# RL7005_IP_SVD register map
Vendor: Realtek
Registers are 32-bit, read-write, reset 0x0 unless marked. A register's access mark holds for its fields unless they carry their own. Offsets are from the block's base; [hi:lo] are bit positions; {n}, {i} and the like mark numbered series.

## TXPWR_CTRL (part 2 of 2)
Base 0x40000000
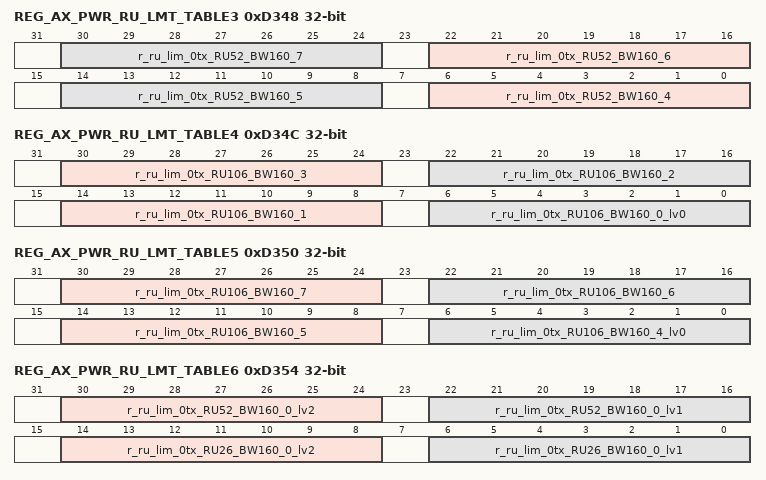
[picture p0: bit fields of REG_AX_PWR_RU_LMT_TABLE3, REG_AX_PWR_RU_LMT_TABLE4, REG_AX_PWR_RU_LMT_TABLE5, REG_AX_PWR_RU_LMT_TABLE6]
0xD348 REG_AX_PWR_RU_LMT_TABLE3
  [8n-26:8n-32] r_ru_lim_0tx_RU52_BW160_{n} (n=4..7) — s(7.1)
0xD34C REG_AX_PWR_RU_LMT_TABLE4
  [30:24] r_ru_lim_0tx_RU106_BW160_3 — s(7.1)
  [22:16] r_ru_lim_0tx_RU106_BW160_2 — s(7.1)
  [14:8] r_ru_lim_0tx_RU106_BW160_1 — s(7.1)
  [6:0] r_ru_lim_0tx_RU106_BW160_0_lv0 — s(7.1)
0xD350 REG_AX_PWR_RU_LMT_TABLE5
  [30:24] r_ru_lim_0tx_RU106_BW160_7 — s(7.1)
  [22:16] r_ru_lim_0tx_RU106_BW160_6 — s(7.1)
  [14:8] r_ru_lim_0tx_RU106_BW160_5 — s(7.1)
  [6:0] r_ru_lim_0tx_RU106_BW160_4_lv0 — s(7.1)
0xD354 REG_AX_PWR_RU_LMT_TABLE6
  [30:24] r_ru_lim_0tx_RU52_BW160_0_lv2 — s(7.1)
  [22:16] r_ru_lim_0tx_RU52_BW160_0_lv1 — s(7.1)
  [14:8] r_ru_lim_0tx_RU26_BW160_0_lv2 — s(7.1)
  [6:0] r_ru_lim_0tx_RU26_BW160_0_lv1 — s(7.1)
0xD358 REG_AX_PWR_RU_LMT_TABLE7
  [6:0] r_ru_lim_0tx_RU106_BW160_0_lv1 — s(7.1)
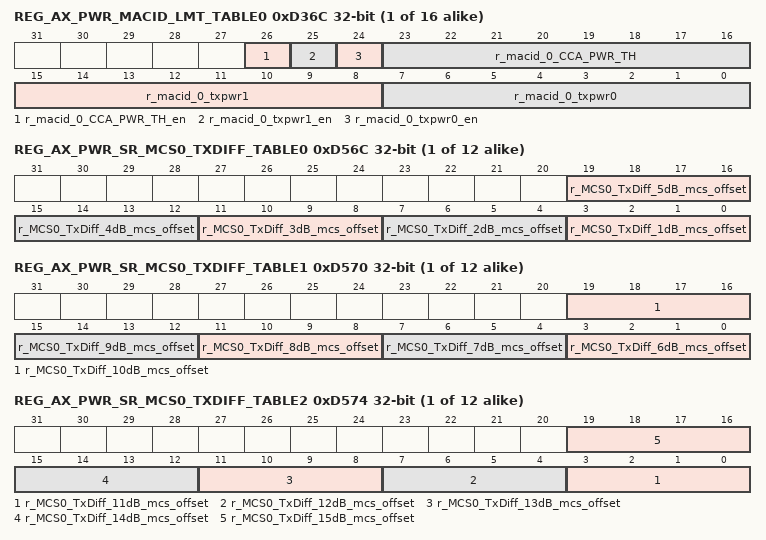
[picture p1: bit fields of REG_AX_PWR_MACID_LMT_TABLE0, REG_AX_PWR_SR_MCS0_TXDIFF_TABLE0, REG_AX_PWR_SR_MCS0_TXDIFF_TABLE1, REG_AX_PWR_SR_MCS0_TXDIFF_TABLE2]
{0xD36C+4i} REG_AX_PWR_MACID_LMT_TABLE{i} (i=0..15)
  [26] r_macid_{i}_CCA_PWR_TH_en — u(1.0)
  [25] r_macid_{i}_txpwr1_en — u(1.0)
  [24] r_macid_{i}_txpwr0_en — u(1.0)
  [23:16] r_macid_{i}_CCA_PWR_TH — s(8.1)
  [15:8] r_macid_{i}_txpwr1 — s(8.1)
  [7:0] r_macid_{i}_txpwr0 — s(8.1)
{0xD56C+0x10*i} REG_AX_PWR_SR_MCS{i}_TXDIFF_TABLE0 (i=0..11)
  [4n-1:4n-4] r_MCS{i}_TxDiff_{n}dB_mcs_offset (n=1..5) — U(4.0) mcs0~11
{0xD570+0x10*i} REG_AX_PWR_SR_MCS{i}_TXDIFF_TABLE1 (i=0..11)
  [4n-21:4n-24] r_MCS{i}_TxDiff_{n}dB_mcs_offset (n=6..10) — U(4.0) mcs0~11
{0xD574+0x10*i} REG_AX_PWR_SR_MCS{i}_TXDIFF_TABLE2 (i=0..11)
  [4n-41:4n-44] r_MCS{i}_TxDiff_{n}dB_mcs_offset (n=11..15) — U(4.0) mcs0~11
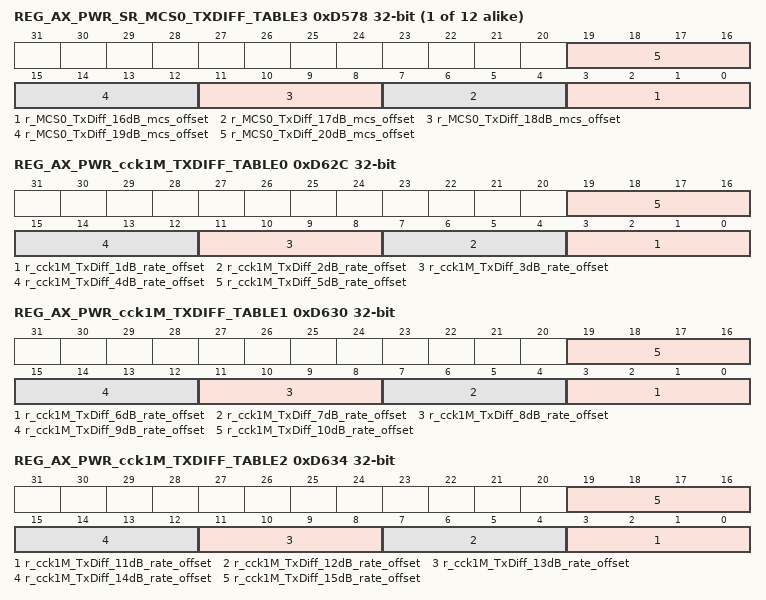
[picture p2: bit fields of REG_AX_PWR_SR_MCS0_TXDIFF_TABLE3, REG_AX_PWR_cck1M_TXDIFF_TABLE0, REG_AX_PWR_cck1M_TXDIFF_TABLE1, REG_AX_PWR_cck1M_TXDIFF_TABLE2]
{0xD578+0x10*i} REG_AX_PWR_SR_MCS{i}_TXDIFF_TABLE3 (i=0..11)
  [4n-61:4n-64] r_MCS{i}_TxDiff_{n}dB_mcs_offset (n=16..20) — U(4.0) mcs0~11
0xD62C REG_AX_PWR_cck1M_TXDIFF_TABLE0
  [4n-1:4n-4] r_cck1M_TxDiff_{n}dB_rate_offset (n=1..5) — U(4.0) cck 0~3, 0-cck1M,1=cck2M,2=cck5p5M,3=cck11M
0xD630 REG_AX_PWR_cck1M_TXDIFF_TABLE1
  [4n-21:4n-24] r_cck1M_TxDiff_{n}dB_rate_offset (n=6..10) — U(4.0) cck 0~3, 0-cck1M,1=cck2M,2=cck5p5M,3=cck11M
0xD634 REG_AX_PWR_cck1M_TXDIFF_TABLE2
  [4n-41:4n-44] r_cck1M_TxDiff_{n}dB_rate_offset (n=11..15) — U(4.0) cck 0~3, 0-cck1M,1=cck2M,2=cck5p5M,3=cck11M
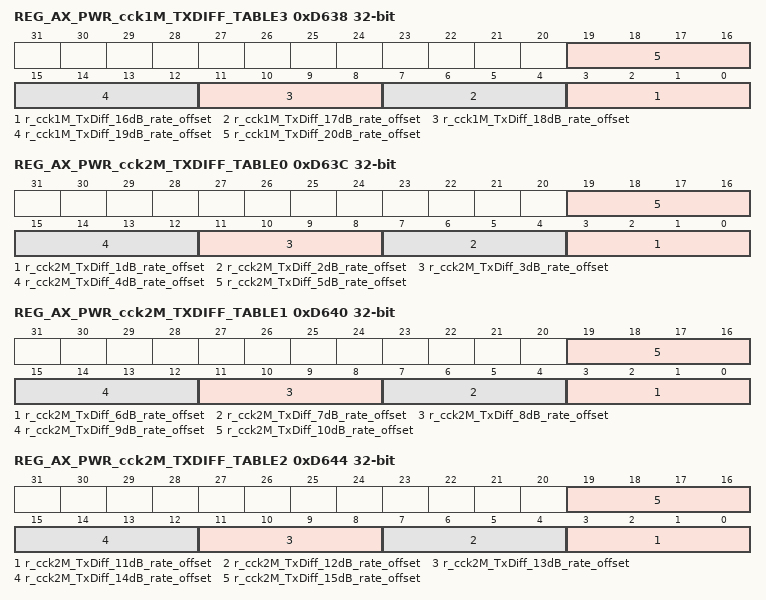
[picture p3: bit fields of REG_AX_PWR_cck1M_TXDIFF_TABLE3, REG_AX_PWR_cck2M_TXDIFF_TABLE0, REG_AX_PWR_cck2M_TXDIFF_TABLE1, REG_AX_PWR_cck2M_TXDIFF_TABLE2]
0xD638 REG_AX_PWR_cck1M_TXDIFF_TABLE3
  [4n-61:4n-64] r_cck1M_TxDiff_{n}dB_rate_offset (n=16..20) — U(4.0) cck 0~3, 0-cck1M,1=cck2M,2=cck5p5M,3=cck11M
0xD63C REG_AX_PWR_cck2M_TXDIFF_TABLE0
  [4n-1:4n-4] r_cck2M_TxDiff_{n}dB_rate_offset (n=1..5) — U(4.0) cck 0~3, 0-cck1M,1=cck2M,2=cck5p5M,3=cck11M
0xD640 REG_AX_PWR_cck2M_TXDIFF_TABLE1
  [4n-21:4n-24] r_cck2M_TxDiff_{n}dB_rate_offset (n=6..10) — U(4.0) cck 0~3, 0-cck1M,1=cck2M,2=cck5p5M,3=cck11M
0xD644 REG_AX_PWR_cck2M_TXDIFF_TABLE2
  [4n-41:4n-44] r_cck2M_TxDiff_{n}dB_rate_offset (n=11..15) — U(4.0) cck 0~3, 0-cck1M,1=cck2M,2=cck5p5M,3=cck11M
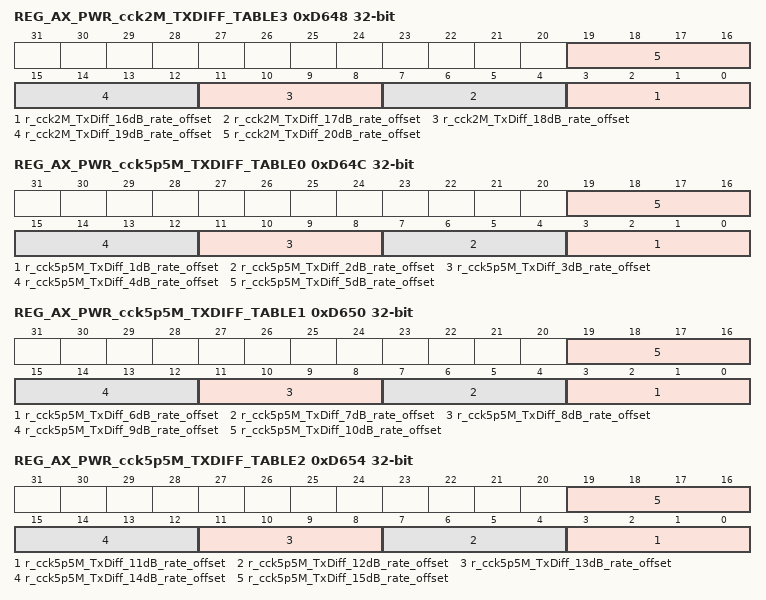
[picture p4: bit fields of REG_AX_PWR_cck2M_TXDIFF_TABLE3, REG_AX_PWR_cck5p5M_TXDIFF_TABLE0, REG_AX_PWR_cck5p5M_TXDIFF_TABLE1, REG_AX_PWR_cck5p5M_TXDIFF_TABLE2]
0xD648 REG_AX_PWR_cck2M_TXDIFF_TABLE3
  [4n-61:4n-64] r_cck2M_TxDiff_{n}dB_rate_offset (n=16..20) — U(4.0) cck 0~3, 0-cck1M,1=cck2M,2=cck5p5M,3=cck11M
0xD64C REG_AX_PWR_cck5p5M_TXDIFF_TABLE0
  [4n-1:4n-4] r_cck5p5M_TxDiff_{n}dB_rate_offset (n=1..5) — U(4.0) cck 0~3, 0-cck1M,1=cck2M,2=cck5p5M,3=cck11M
0xD650 REG_AX_PWR_cck5p5M_TXDIFF_TABLE1
  [4n-21:4n-24] r_cck5p5M_TxDiff_{n}dB_rate_offset (n=6..10) — U(4.0) cck 0~3, 0-cck1M,1=cck2M,2=cck5p5M,3=cck11M
0xD654 REG_AX_PWR_cck5p5M_TXDIFF_TABLE2
  [4n-41:4n-44] r_cck5p5M_TxDiff_{n}dB_rate_offset (n=11..15) — U(4.0) cck 0~3, 0-cck1M,1=cck2M,2=cck5p5M,3=cck11M
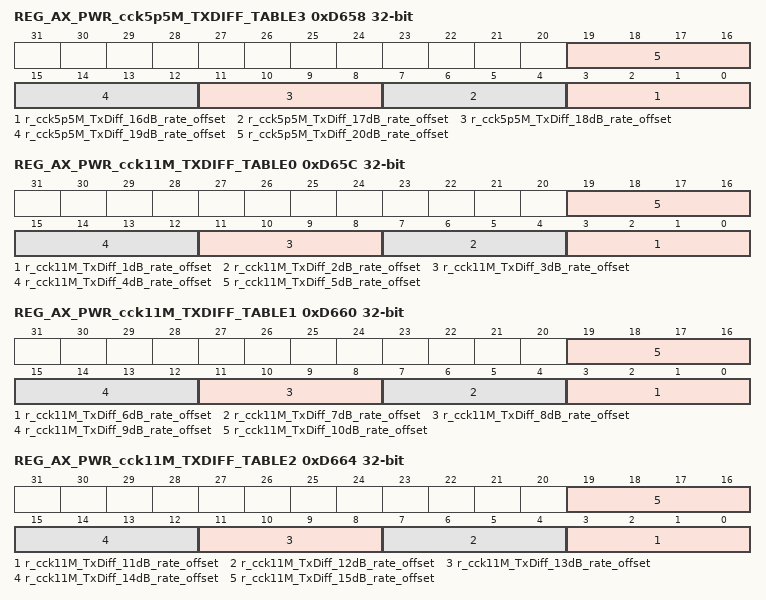
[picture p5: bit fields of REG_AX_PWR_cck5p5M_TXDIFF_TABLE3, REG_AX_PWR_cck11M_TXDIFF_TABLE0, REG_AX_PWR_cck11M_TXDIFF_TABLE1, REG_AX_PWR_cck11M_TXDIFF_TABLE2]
0xD658 REG_AX_PWR_cck5p5M_TXDIFF_TABLE3
  [4n-61:4n-64] r_cck5p5M_TxDiff_{n}dB_rate_offset (n=16..20) — U(4.0) cck 0~3, 0-cck1M,1=cck2M,2=cck5p5M,3=cck11M
0xD65C REG_AX_PWR_cck11M_TXDIFF_TABLE0
  [4n-1:4n-4] r_cck11M_TxDiff_{n}dB_rate_offset (n=1..5) — U(4.0) cck 0~3, 0-cck1M,1=cck2M,2=cck5p5M,3=cck11M
0xD660 REG_AX_PWR_cck11M_TXDIFF_TABLE1
  [4n-21:4n-24] r_cck11M_TxDiff_{n}dB_rate_offset (n=6..10) — U(4.0) cck 0~3, 0-cck1M,1=cck2M,2=cck5p5M,3=cck11M
0xD664 REG_AX_PWR_cck11M_TXDIFF_TABLE2
  [4n-41:4n-44] r_cck11M_TxDiff_{n}dB_rate_offset (n=11..15) — U(4.0) cck 0~3, 0-cck1M,1=cck2M,2=cck5p5M,3=cck11M
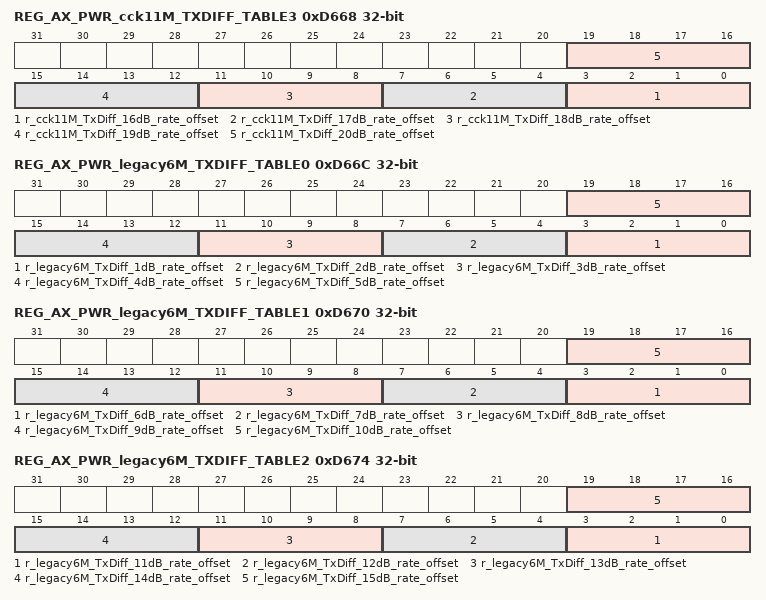
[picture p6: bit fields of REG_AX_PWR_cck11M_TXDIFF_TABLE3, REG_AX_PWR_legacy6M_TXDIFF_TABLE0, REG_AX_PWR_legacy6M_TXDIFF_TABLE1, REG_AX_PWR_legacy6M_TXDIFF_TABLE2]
0xD668 REG_AX_PWR_cck11M_TXDIFF_TABLE3
  [4n-61:4n-64] r_cck11M_TxDiff_{n}dB_rate_offset (n=16..20) — U(4.0) cck 0~3, 0-cck1M,1=cck2M,2=cck5p5M,3=cck11M
0xD66C REG_AX_PWR_legacy6M_TXDIFF_TABLE0
  [4n-1:4n-4] r_legacy6M_TxDiff_{n}dB_rate_offset (n=1..5) — U(4.0) legacy 4~11,4=legacy6M,5=legacy9M,6=legacy12M,7=legacy18M,8=legacy24M,9=legacy36M,10=legacy48M,11=legacy54M
0xD670 REG_AX_PWR_legacy6M_TXDIFF_TABLE1
  [4n-21:4n-24] r_legacy6M_TxDiff_{n}dB_rate_offset (n=6..10) — U(4.0) legacy 4~11,4=legacy6M,5=legacy9M,6=legacy12M,7=legacy18M,8=legacy24M,9=legacy36M,10=legacy48M,11=legacy54M
0xD674 REG_AX_PWR_legacy6M_TXDIFF_TABLE2
  [4n-41:4n-44] r_legacy6M_TxDiff_{n}dB_rate_offset (n=11..15) — U(4.0) legacy 4~11,4=legacy6M,5=legacy9M,6=legacy12M,7=legacy18M,8=legacy24M,9=legacy36M,10=legacy48M,11=legacy54M
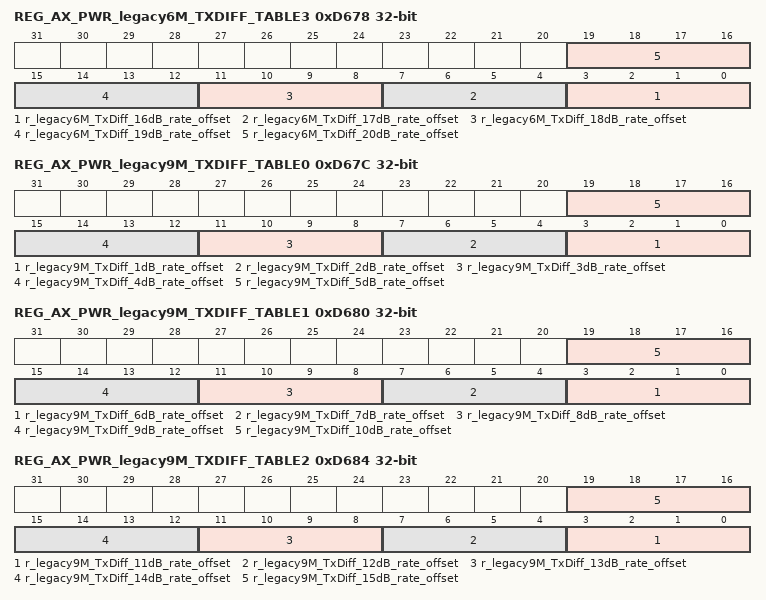
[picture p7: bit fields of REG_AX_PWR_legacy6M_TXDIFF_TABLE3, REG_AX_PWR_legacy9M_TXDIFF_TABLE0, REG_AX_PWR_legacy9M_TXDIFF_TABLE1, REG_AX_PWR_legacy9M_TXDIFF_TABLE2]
0xD678 REG_AX_PWR_legacy6M_TXDIFF_TABLE3
  [4n-61:4n-64] r_legacy6M_TxDiff_{n}dB_rate_offset (n=16..20) — U(4.0) legacy 4~11,4=legacy6M,5=legacy9M,6=legacy12M,7=legacy18M,8=legacy24M,9=legacy36M,10=legacy48M,11=legacy54M
0xD67C REG_AX_PWR_legacy9M_TXDIFF_TABLE0
  [4n-1:4n-4] r_legacy9M_TxDiff_{n}dB_rate_offset (n=1..5) — U(4.0) legacy 4~11,4=legacy6M,5=legacy9M,6=legacy12M,7=legacy18M,8=legacy24M,9=legacy36M,10=legacy48M,11=legacy54M
0xD680 REG_AX_PWR_legacy9M_TXDIFF_TABLE1
  [4n-21:4n-24] r_legacy9M_TxDiff_{n}dB_rate_offset (n=6..10) — U(4.0) legacy 4~11,4=legacy6M,5=legacy9M,6=legacy12M,7=legacy18M,8=legacy24M,9=legacy36M,10=legacy48M,11=legacy54M
0xD684 REG_AX_PWR_legacy9M_TXDIFF_TABLE2
  [4n-41:4n-44] r_legacy9M_TxDiff_{n}dB_rate_offset (n=11..15) — U(4.0) legacy 4~11,4=legacy6M,5=legacy9M,6=legacy12M,7=legacy18M,8=legacy24M,9=legacy36M,10=legacy48M,11=legacy54M
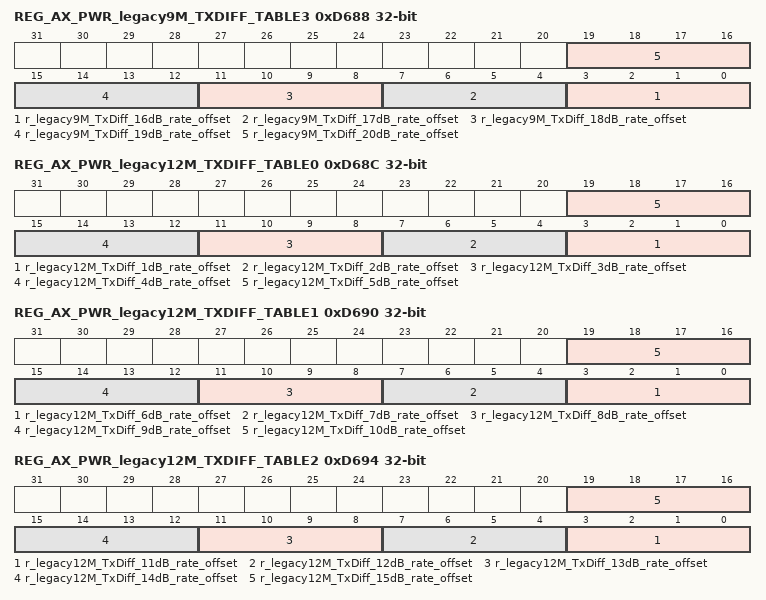
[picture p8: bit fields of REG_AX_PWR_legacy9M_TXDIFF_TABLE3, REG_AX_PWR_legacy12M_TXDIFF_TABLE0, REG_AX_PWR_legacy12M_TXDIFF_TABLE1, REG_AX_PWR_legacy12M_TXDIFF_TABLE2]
0xD688 REG_AX_PWR_legacy9M_TXDIFF_TABLE3
  [4n-61:4n-64] r_legacy9M_TxDiff_{n}dB_rate_offset (n=16..20) — U(4.0) legacy 4~11,4=legacy6M,5=legacy9M,6=legacy12M,7=legacy18M,8=legacy24M,9=legacy36M,10=legacy48M,11=legacy54M
0xD68C REG_AX_PWR_legacy12M_TXDIFF_TABLE0
  [4n-1:4n-4] r_legacy12M_TxDiff_{n}dB_rate_offset (n=1..5) — U(4.0) legacy 4~11,4=legacy6M,5=legacy9M,6=legacy12M,7=legacy18M,8=legacy24M,9=legacy36M,10=legacy48M,11=legacy54M
0xD690 REG_AX_PWR_legacy12M_TXDIFF_TABLE1
  [4n-21:4n-24] r_legacy12M_TxDiff_{n}dB_rate_offset (n=6..10) — U(4.0) legacy 4~11,4=legacy6M,5=legacy9M,6=legacy12M,7=legacy18M,8=legacy24M,9=legacy36M,10=legacy48M,11=legacy54M
0xD694 REG_AX_PWR_legacy12M_TXDIFF_TABLE2
  [4n-41:4n-44] r_legacy12M_TxDiff_{n}dB_rate_offset (n=11..15) — U(4.0) legacy 4~11,4=legacy6M,5=legacy9M,6=legacy12M,7=legacy18M,8=legacy24M,9=legacy36M,10=legacy48M,11=legacy54M
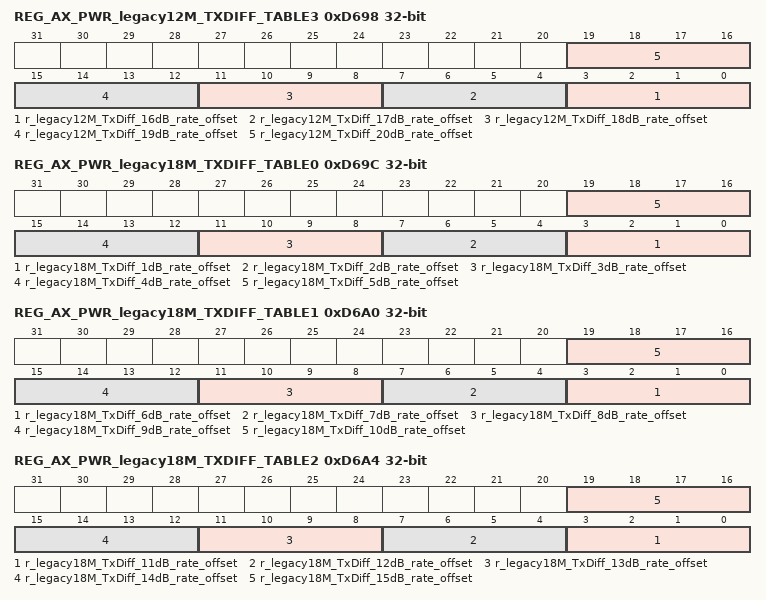
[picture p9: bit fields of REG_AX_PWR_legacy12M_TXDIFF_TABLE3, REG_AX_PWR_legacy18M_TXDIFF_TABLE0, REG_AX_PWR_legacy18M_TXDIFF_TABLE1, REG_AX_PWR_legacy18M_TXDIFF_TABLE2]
0xD698 REG_AX_PWR_legacy12M_TXDIFF_TABLE3
  [4n-61:4n-64] r_legacy12M_TxDiff_{n}dB_rate_offset (n=16..20) — U(4.0) legacy 4~11,4=legacy6M,5=legacy9M,6=legacy12M,7=legacy18M,8=legacy24M,9=legacy36M,10=legacy48M,11=legacy54M
0xD69C REG_AX_PWR_legacy18M_TXDIFF_TABLE0
  [4n-1:4n-4] r_legacy18M_TxDiff_{n}dB_rate_offset (n=1..5) — U(4.0) legacy 4~11,4=legacy6M,5=legacy9M,6=legacy12M,7=legacy18M,8=legacy24M,9=legacy36M,10=legacy48M,11=legacy54M
0xD6A0 REG_AX_PWR_legacy18M_TXDIFF_TABLE1
  [4n-21:4n-24] r_legacy18M_TxDiff_{n}dB_rate_offset (n=6..10) — U(4.0) legacy 4~11,4=legacy6M,5=legacy9M,6=legacy12M,7=legacy18M,8=legacy24M,9=legacy36M,10=legacy48M,11=legacy54M
0xD6A4 REG_AX_PWR_legacy18M_TXDIFF_TABLE2
  [4n-41:4n-44] r_legacy18M_TxDiff_{n}dB_rate_offset (n=11..15) — U(4.0) legacy 4~11,4=legacy6M,5=legacy9M,6=legacy12M,7=legacy18M,8=legacy24M,9=legacy36M,10=legacy48M,11=legacy54M
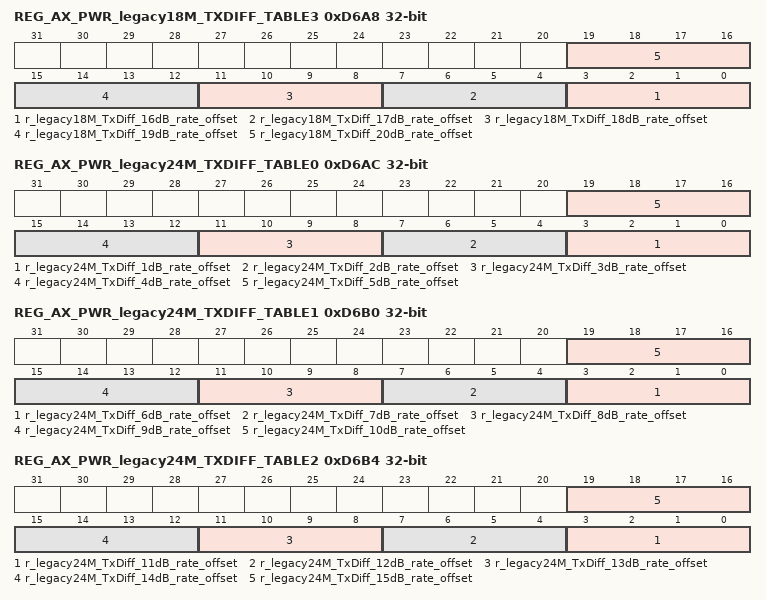
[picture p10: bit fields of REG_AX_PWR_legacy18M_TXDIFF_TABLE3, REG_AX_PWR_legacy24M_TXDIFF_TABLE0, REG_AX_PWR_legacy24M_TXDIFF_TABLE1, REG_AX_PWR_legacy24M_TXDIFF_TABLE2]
0xD6A8 REG_AX_PWR_legacy18M_TXDIFF_TABLE3
  [4n-61:4n-64] r_legacy18M_TxDiff_{n}dB_rate_offset (n=16..20) — U(4.0) legacy 4~11,4=legacy6M,5=legacy9M,6=legacy12M,7=legacy18M,8=legacy24M,9=legacy36M,10=legacy48M,11=legacy54M
0xD6AC REG_AX_PWR_legacy24M_TXDIFF_TABLE0
  [4n-1:4n-4] r_legacy24M_TxDiff_{n}dB_rate_offset (n=1..5) — U(4.0) legacy 4~11,4=legacy6M,5=legacy9M,6=legacy12M,7=legacy18M,8=legacy24M,9=legacy36M,10=legacy48M,11=legacy54M
0xD6B0 REG_AX_PWR_legacy24M_TXDIFF_TABLE1
  [4n-21:4n-24] r_legacy24M_TxDiff_{n}dB_rate_offset (n=6..10) — U(4.0) legacy 4~11,4=legacy6M,5=legacy9M,6=legacy12M,7=legacy18M,8=legacy24M,9=legacy36M,10=legacy48M,11=legacy54M
0xD6B4 REG_AX_PWR_legacy24M_TXDIFF_TABLE2
  [4n-41:4n-44] r_legacy24M_TxDiff_{n}dB_rate_offset (n=11..15) — U(4.0) legacy 4~11,4=legacy6M,5=legacy9M,6=legacy12M,7=legacy18M,8=legacy24M,9=legacy36M,10=legacy48M,11=legacy54M
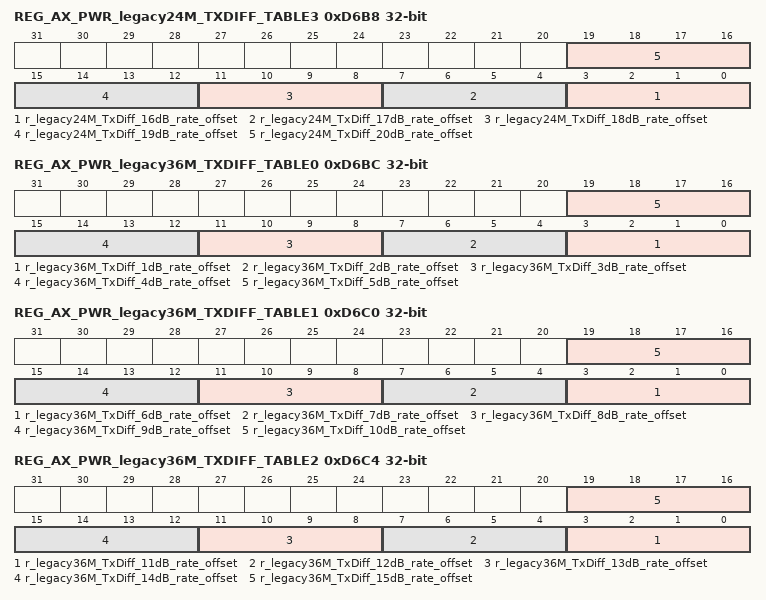
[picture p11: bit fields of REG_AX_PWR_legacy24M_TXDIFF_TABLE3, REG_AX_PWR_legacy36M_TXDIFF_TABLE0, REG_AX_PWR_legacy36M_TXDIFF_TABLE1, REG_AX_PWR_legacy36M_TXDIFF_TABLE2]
0xD6B8 REG_AX_PWR_legacy24M_TXDIFF_TABLE3
  [4n-61:4n-64] r_legacy24M_TxDiff_{n}dB_rate_offset (n=16..20) — U(4.0) legacy 4~11,4=legacy6M,5=legacy9M,6=legacy12M,7=legacy18M,8=legacy24M,9=legacy36M,10=legacy48M,11=legacy54M
0xD6BC REG_AX_PWR_legacy36M_TXDIFF_TABLE0
  [4n-1:4n-4] r_legacy36M_TxDiff_{n}dB_rate_offset (n=1..5) — U(4.0) legacy 4~11,4=legacy6M,5=legacy9M,6=legacy12M,7=legacy18M,8=legacy24M,9=legacy36M,10=legacy48M,11=legacy54M
0xD6C0 REG_AX_PWR_legacy36M_TXDIFF_TABLE1
  [4n-21:4n-24] r_legacy36M_TxDiff_{n}dB_rate_offset (n=6..10) — U(4.0) legacy 4~11,4=legacy6M,5=legacy9M,6=legacy12M,7=legacy18M,8=legacy24M,9=legacy36M,10=legacy48M,11=legacy54M
0xD6C4 REG_AX_PWR_legacy36M_TXDIFF_TABLE2
  [4n-41:4n-44] r_legacy36M_TxDiff_{n}dB_rate_offset (n=11..15) — U(4.0) legacy 4~11,4=legacy6M,5=legacy9M,6=legacy12M,7=legacy18M,8=legacy24M,9=legacy36M,10=legacy48M,11=legacy54M
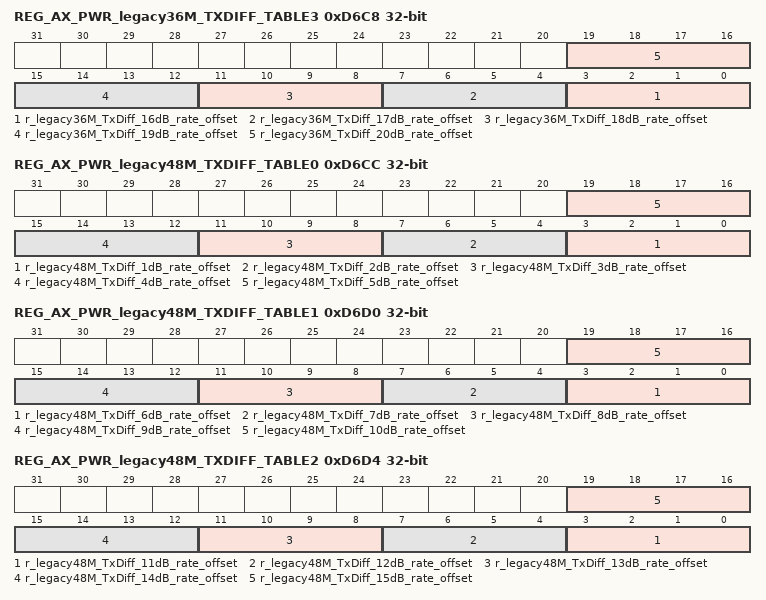
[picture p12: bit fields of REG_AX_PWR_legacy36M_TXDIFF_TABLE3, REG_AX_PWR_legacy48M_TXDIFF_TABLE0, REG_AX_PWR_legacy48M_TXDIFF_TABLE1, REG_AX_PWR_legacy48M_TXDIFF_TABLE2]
0xD6C8 REG_AX_PWR_legacy36M_TXDIFF_TABLE3
  [4n-61:4n-64] r_legacy36M_TxDiff_{n}dB_rate_offset (n=16..20) — U(4.0) legacy 4~11,4=legacy6M,5=legacy9M,6=legacy12M,7=legacy18M,8=legacy24M,9=legacy36M,10=legacy48M,11=legacy54M
0xD6CC REG_AX_PWR_legacy48M_TXDIFF_TABLE0
  [4n-1:4n-4] r_legacy48M_TxDiff_{n}dB_rate_offset (n=1..5) — U(4.0) legacy 4~11,4=legacy6M,5=legacy9M,6=legacy12M,7=legacy18M,8=legacy24M,9=legacy36M,10=legacy48M,11=legacy54M
0xD6D0 REG_AX_PWR_legacy48M_TXDIFF_TABLE1
  [4n-21:4n-24] r_legacy48M_TxDiff_{n}dB_rate_offset (n=6..10) — U(4.0) legacy 4~11,4=legacy6M,5=legacy9M,6=legacy12M,7=legacy18M,8=legacy24M,9=legacy36M,10=legacy48M,11=legacy54M
0xD6D4 REG_AX_PWR_legacy48M_TXDIFF_TABLE2
  [4n-41:4n-44] r_legacy48M_TxDiff_{n}dB_rate_offset (n=11..15) — U(4.0) legacy 4~11,4=legacy6M,5=legacy9M,6=legacy12M,7=legacy18M,8=legacy24M,9=legacy36M,10=legacy48M,11=legacy54M
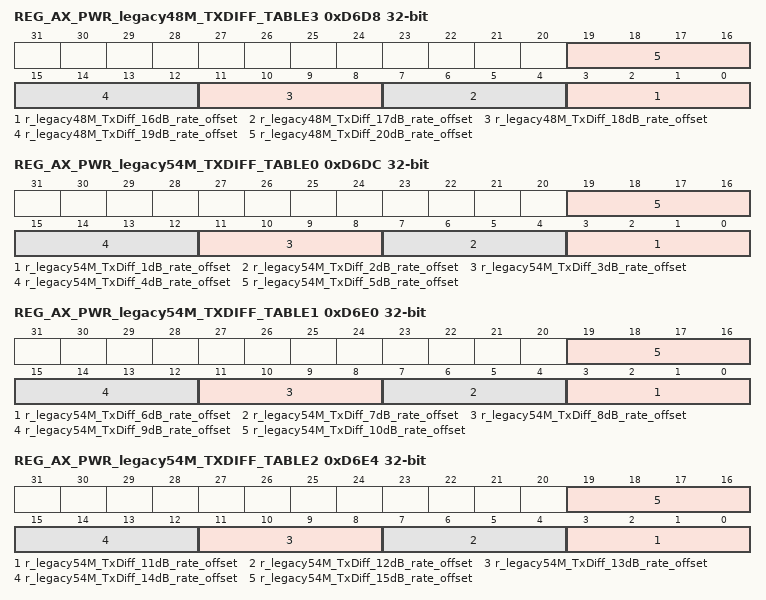
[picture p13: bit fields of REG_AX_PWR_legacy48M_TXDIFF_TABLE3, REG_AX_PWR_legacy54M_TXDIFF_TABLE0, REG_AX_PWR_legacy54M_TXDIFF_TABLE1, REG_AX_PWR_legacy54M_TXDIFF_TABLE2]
0xD6D8 REG_AX_PWR_legacy48M_TXDIFF_TABLE3
  [4n-61:4n-64] r_legacy48M_TxDiff_{n}dB_rate_offset (n=16..20) — U(4.0) legacy 4~11,4=legacy6M,5=legacy9M,6=legacy12M,7=legacy18M,8=legacy24M,9=legacy36M,10=legacy48M,11=legacy54M
0xD6DC REG_AX_PWR_legacy54M_TXDIFF_TABLE0
  [4n-1:4n-4] r_legacy54M_TxDiff_{n}dB_rate_offset (n=1..5) — U(4.0) legacy 4~11,4=legacy6M,5=legacy9M,6=legacy12M,7=legacy18M,8=legacy24M,9=legacy36M,10=legacy48M,11=legacy54M
0xD6E0 REG_AX_PWR_legacy54M_TXDIFF_TABLE1
  [4n-21:4n-24] r_legacy54M_TxDiff_{n}dB_rate_offset (n=6..10) — U(4.0) legacy 4~11,4=legacy6M,5=legacy9M,6=legacy12M,7=legacy18M,8=legacy24M,9=legacy36M,10=legacy48M,11=legacy54M
0xD6E4 REG_AX_PWR_legacy54M_TXDIFF_TABLE2
  [4n-41:4n-44] r_legacy54M_TxDiff_{n}dB_rate_offset (n=11..15) — U(4.0) legacy 4~11,4=legacy6M,5=legacy9M,6=legacy12M,7=legacy18M,8=legacy24M,9=legacy36M,10=legacy48M,11=legacy54M
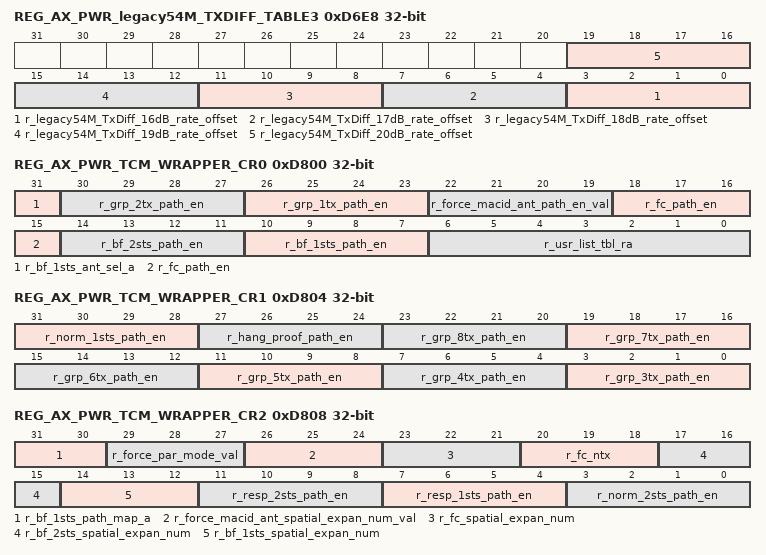
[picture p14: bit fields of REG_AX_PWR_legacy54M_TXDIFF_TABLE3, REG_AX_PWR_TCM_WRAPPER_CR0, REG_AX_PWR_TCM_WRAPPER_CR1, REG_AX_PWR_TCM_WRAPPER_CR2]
0xD6E8 REG_AX_PWR_legacy54M_TXDIFF_TABLE3
  [4n-61:4n-64] r_legacy54M_TxDiff_{n}dB_rate_offset (n=16..20) — U(4.0) legacy 4~11,4=legacy6M,5=legacy9M,6=legacy12M,7=legacy18M,8=legacy24M,9=legacy36M,10=legacy48M,11=legacy54M
0xD800 REG_AX_PWR_TCM_WRAPPER_CR0
  [31] r_bf_1sts_ant_sel_a, [30:27] r_grp_2tx_path_en, [26:23] r_grp_1tx_path_en, [22:19] r_force_macid_ant_path_en_val, [18:15] r_fc_path_en, [14:11] r_bf_2sts_path_en, [10:7] r_bf_1sts_path_en, [6:0] r_usr_list_tbl_ra
0xD804 REG_AX_PWR_TCM_WRAPPER_CR1
  [31:28] r_norm_1sts_path_en, [27:24] r_hang_proof_path_en, [4n-9:4n-12] r_grp_{n}tx_path_en (n=3..8)
0xD808 REG_AX_PWR_TCM_WRAPPER_CR2
  [31:30] r_bf_1sts_path_map_a, [29:27] r_force_par_mode_val, [26:24] r_force_macid_ant_spatial_expan_num_val, [23:21] r_fc_spatial_expan_num, [20:18] r_fc_ntx, [17:15] r_bf_2sts_spatial_expan_num, [14:12] r_bf_1sts_spatial_expan_num, [11:8] r_resp_2sts_path_en, [7:4] r_resp_1sts_path_en, [3:0] r_norm_2sts_path_en
0xD80C REG_AX_PWR_TCM_WRAPPER_CR3
  [31:30] r_bf_1sts_path_map_b, [29:27] r_norm_1sts_spatial_expan_num, [26:24] r_hang_proof_spatial_expan_num, [3n-1:3n-3] r_grp_{n}tx_spatial_expan_num (n=1..8)
0xD810 REG_AX_PWR_TCM_WRAPPER_CR4
  [31] r_bf_1sts_ant_sel_b, [30:29] r_force_macid_ant_map_a_val, [28:27] r_fc_path_map_d, [26:25] r_fc_path_map_c, [24:23] r_fc_path_map_b, [22:21] r_fc_path_map_a, [20:19] r_bf_2sts_path_map_d, [18:17] r_bf_2sts_path_map_c, [16:15] r_bf_2sts_path_map_b, [14:13] r_bf_2sts_path_map_a, [12:11] r_bf_1sts_path_map_d, [10:9] r_bf_1sts_path_map_c, [8:6] r_resp_2sts_spatial_expan_num, [5:3] r_resp_1sts_spatial_expan_num, [2:0] r_norm_2sts_spatial_expan_num
0xD814 REG_AX_PWR_TCM_WRAPPER_CR5
  [8n-1:8n-2] r_grp_{n}tx_path_map_a (n=1..4), [29:28] r_grp_3tx_path_map_d, [27:26] r_grp_3tx_path_map_c, [25:24] r_grp_3tx_path_map_b, [21:20] r_grp_2tx_path_map_d, [19:18] r_grp_2tx_path_map_c, [17:16] r_grp_2tx_path_map_b, [13:12] r_grp_1tx_path_map_d, [11:10] r_grp_1tx_path_map_c, [9:8] r_grp_1tx_path_map_b, [5:4] r_force_macid_ant_map_d_val, [3:2] r_force_macid_ant_map_c_val, [1:0] r_force_macid_ant_map_b_val
0xD818 REG_AX_PWR_TCM_WRAPPER_CR6
  [8n-33:8n-34] r_grp_{n}tx_path_map_a (n=5..8), [8n-27:8n-28] r_grp_{n}tx_path_map_d (n=4..7), [8n-29:8n-30] r_grp_{n}tx_path_map_c (n=4..7), [8n-31:8n-32] r_grp_{n}tx_path_map_b (n=4..7)
0xD81C REG_AX_PWR_TCM_WRAPPER_CR7
  [31:30] r_resp_1sts_path_map_a, [29:28] r_norm_2sts_path_map_d, [27:26] r_norm_2sts_path_map_c, [25:24] r_norm_2sts_path_map_b, [23:22] r_norm_2sts_path_map_a, [21:20] r_norm_1sts_path_map_d, [19:18] r_norm_1sts_path_map_c, [17:16] r_norm_1sts_path_map_b, [15:14] r_norm_1sts_path_map_a, [13:12] r_hang_proof_path_map_d, [11:10] r_hang_proof_path_map_c, [9:8] r_hang_proof_path_map_b, [7:6] r_hang_proof_path_map_a, [5:4] r_grp_8tx_path_map_d, [3:2] r_grp_8tx_path_map_c, [1:0] r_grp_8tx_path_map_b
0xD820 REG_AX_PWR_TCM_WRAPPER_CR8
  [31] r_fc_ntx_en, [30] r_fc_ant_sel_d_en, [29] r_fc_ant_sel_d, [28] r_fc_ant_sel_c_en, [27] r_fc_ant_sel_c, [26] r_fc_ant_sel_b_en, [25] r_fc_ant_sel_b, [24] r_fc_ant_sel_a_en, [23] r_fc_ant_sel_a, [22] r_clr_proof_cnt, [21] r_cbw80p80_en, [20] r_bypass_ant_sel_hetb_bw80p80_en, [19] r_bf_2sts_ant_sel_d, [18] r_bf_2sts_ant_sel_c, [17] r_bf_2sts_ant_sel_b, [16] r_bf_2sts_ant_sel_a, [15] r_bf_1sts_ant_sel_d, [14] r_bf_1sts_ant_sel_c, [13:12] r_resp_2sts_path_map_d, [11:10] r_resp_2sts_path_map_c, [9:8] r_resp_2sts_path_map_b, [7:6] r_resp_2sts_path_map_a, [5:4] r_resp_1sts_path_map_d, [3:2] r_resp_1sts_path_map_c, [1:0] r_resp_1sts_path_map_b
0xD824 REG_AX_PWR_TCM_WRAPPER_CR9
  [31] r_grp_2tx_ant_sel_c, [30] r_grp_2tx_ant_sel_b, [29] r_grp_2tx_ant_sel_a, [28] r_grp_1tx_ant_sel_d, [27] r_grp_1tx_ant_sel_c, [26] r_grp_1tx_ant_sel_b, [25] r_grp_1tx_ant_sel_a, [24] r_force_par_mode_on, [23] r_force_macid_input_mumimo_nsts_hang_proof_en_val, [22] r_force_macid_input_mumimo_nsts_hang_proof_en_on, [21] r_force_macid_hang_proof_en_val, [20] r_force_macid_hang_proof_en_on, [19] r_force_macid_ant_spatial_expan_num_on, [18] r_force_macid_ant_sel_d_val, [17] r_force_macid_ant_sel_d_on, [16] r_force_macid_ant_sel_c_val, [15] r_force_macid_ant_sel_c_on, [14] r_force_macid_ant_sel_b_val, [13] r_force_macid_ant_sel_b_on, [12] r_force_macid_ant_sel_a_val, [11] r_force_macid_ant_sel_a_on, [10] r_force_macid_ant_path_en_on, [9] r_force_macid_ant_map_d_on, [8] r_force_macid_ant_map_c_on, [7] r_force_macid_ant_map_b_on, [6] r_force_macid_ant_map_a_on, [5] r_fc_spatial_expan_num_en, [4] r_fc_path_map_d_en, [3] r_fc_path_map_c_en, [2] r_fc_path_map_b_en, [1] r_fc_path_map_a_en, [0] r_fc_path_en_en
0xD828 REG_AX_PWR_TCM_WRAPPER_CR10
  [31] r_input_mumimo_nsts_hang_proof_en, [30] r_hang_proof_opt, [29] r_hang_proof_en, [28] r_hang_proof_ant_sel_d, [27] r_hang_proof_ant_sel_c, [26] r_hang_proof_ant_sel_b, [25] r_hang_proof_ant_sel_a, [4n-8] r_grp_{n}tx_ant_sel_d (n=2..8), [4n-9] r_grp_{n}tx_ant_sel_c (n=3..8), [4n-10] r_grp_{n}tx_ant_sel_b (n=3..8), [4n-11] r_grp_{n}tx_ant_sel_a (n=3..8)
0xD82C REG_AX_PWR_TCM_WRAPPER_CR11
  [20] r_force_hang_proof_on, [19] r_usr_list_tbl_rd, [18] r_resp_2stsant_sel_d, [17] r_resp_2stsant_sel_c, [16] r_resp_2stsant_sel_b, [15] r_resp_2stsant_sel_a, [14] r_resp_1stsant_sel_d, [13] r_resp_1stsant_sel_c, [12] r_resp_1stsant_sel_b, [11] r_resp_1stsant_sel_a, [10] r_norm_2stsant_sel_d, [9] r_norm_2stsant_sel_c, [8] r_norm_2stsant_sel_b, [7] r_norm_2stsant_sel_a, [6] r_norm_1stsant_sel_d, [5] r_norm_1stsant_sel_c, [4] r_norm_1stsant_sel_b, [3] r_norm_1stsant_sel_a, [2] r_n_tx_cal_mod_hang_proof, [1] r_n_tx_cal_mod, [0] r_input_mumimo_nsts_hang_proof_opt
0xD830 REG_AX_PWR_TCM_WRAPPER_CR12
  [31:26] r_force_pwrsr_txpwr_pd_val, [25:18] r_force_pwrcom_ru_alloc_val, [17:9] r_force_pwrul_rpl_val, [8:0] r_force_pwrul_rpl_up_val
0xD834 REG_AX_PWR_TCM_WRAPPER_CR13
  [31:28] r_dbg_ant_sel, [27:22] r_force_pwrsr_txpwr_toler_val, [21:15] r_force_pwrul_tar_rssi_val, [14:8] r_force_pwrcom_macid_val, [7:0] r_force_pwrru_ch20_with_data_val
0xD838 REG_AX_PWR_TCM_WRAPPER_CR14
  [31:29] r_force_pwrcom_ctrl_val, [28:26] r_force_pwrant_nsts_val, [25:23] r_force_macid_pwr_mode_val, [22:19] r_force_pwrcom_txsc_val, [18:15] r_force_pwrcom_ppdu_type_val, [14:11] r_force_out_pwrcom_max_mcs_val, [10:6] r_force_pwrcom_mcs_val, [5:0] r_force_pwrul_ap_tx_pwr_val
0xD83C REG_AX_PWR_TCM_WRAPPER_CR15
  [31] r_force_macid_txbf_en_val, [30] r_force_macid_txbf_en_on, [29] r_force_macid_resp_en_val, [28] r_force_macid_resp_en_on, [27] r_force_macid_pwr_mode_on, [26] r_force_macid_norm_en_val, [25] r_force_macid_norm_en_on, [24] r_force_macid_ndp_en_val, [23] r_force_macid_ndp_en_on, [22] r_force_macid_mumimo_en_val, [21] r_force_macid_mumimo_en_on, [20] r_force_macid_cca_th_allow_val, [19] r_force_macid_cca_th_allow_on, [18] r_force_cca_th_allow_val, [17] r_force_cca_th_allow_on, [16] r_clr_ant_set, [15] r_ant_sel_dbg_en, [8:7] r_force_pwrcom_precoding_mode_idx_val, [6:5] r_force_pwrcom_dbw_idx_val, [4:3] r_force_pwrcom_cbw_idx_val, [2:0] r_force_pwrru_grp_ntx_val
0xD840 REG_AX_PWR_TCM_WRAPPER_CR16
  [31] r_force_pwrul_rpl_up_en_on, [30] r_force_pwrul_rpl_on, [29] r_force_pwrul_ap_tx_pwr_on, [28] r_force_pwrtssi_fast_mode_en_val, [27] r_force_pwrtssi_fast_mode_en_on, [26] r_force_pwrsr_txpwr_toler_on, [25] r_force_pwrsr_txpwr_pd_on, [24] r_force_pwrru_grp_ntx_on, [23] r_force_pwrru_ch20_with_data_on, [22] r_force_pwrcom_txsc_on, [21] r_force_pwrcom_stbc_en_val, [20] r_force_pwrcom_stbc_en_on, [19] r_force_pwrcom_rx_lte_val, [18] r_force_pwrcom_rx_lte_on, [17] r_force_pwrcom_ru_alloc_on, [16] r_force_pwrcom_precoding_mode_idx_on, [15] r_force_pwrcom_ppdu_type_on, [14] r_force_pwrcom_mcs_on, [13] r_force_pwrcom_macid_on, [12] r_force_pwrcom_dcm_val, [11] r_force_pwrcom_dcm_on, [10] r_force_pwrcom_dbw_idx_on, [9] r_force_pwrcom_ctrl_reg_val, [8] r_force_pwrcom_ctrl_reg_on, [7] r_force_pwrcom_ctrl_on, [6] r_force_pwrcom_cbw_idx_on, [5] r_force_pwrant_nsts_on, [4] r_force_pwrant_ndp_en_val, [3] r_force_pwrant_ndp_en_on, [2] r_force_pwrant_active_tx_en_val, [1] r_force_pwrant_active_tx_en_on, [0] r_force_out_pwrcom_max_mcs_on
0xD844 REG_AX_PWR_TCM_WRAPPER_CR17
  [9] r_tssi_ctrl_mac_pwrcom_ch20_with_data_bit_rev, [8] r_tssi_ctrl_mac_pwrcom_ch20_with_data_bit_inv, [7] r_sr_mcs_mask_dis, [6] r_pwrru_ch20_with_data_hang_proof_en, [5] r_mumimo_apply_pwrlimbf_en, [4] r_heru_mask_dis, [3] r_heru_ch20_with_data_from_f2p_dis, [2] r_force_pwrul_tar_rssi_on, [1] r_force_pwrul_rpl_up_on, [0] r_force_pwrul_rpl_up_en_val
0xD848 REG_AX_PWR_TCM_WRAPPER_CR18
  [28] r_ru_alloc_dbw160_fix_en, [27] r_pwrtssict_tx_bandedge_cfg_force_out_on, [26] r_pwrtssict_tssi_msr_athestf_force_out_val, [25] r_pwrtssict_tssi_msr_athestf_force_out_on, [24] r_pwrtssict_tssi_fast_mode_en_force_out_val, [23] r_pwrtssict_tssi_fast_mode_en_force_out_on, [22] r_pwrtssict_tssi_diff_seg0_db_force_out_on, [21] r_pwrtssict_pwr_ofst_seg0_db_force_out_on, [20] r_MAC_def_legacy_rate_idx_begin_at_4_on, [19:18] r_pwrtssict_tx_bandedge_cfg_force_out_val, [17:9] r_pwrtssict_tssi_diff_seg0_db_force_out_val, [8:0] r_pwrtssict_pwr_ofst_seg0_db_force_out_val
0xD900 REG_DUMMY_TXPWR
  [31:0] dummy
0xD908 REG_AX_PWR_TSSI_TABLE0
  [8n+7:8n] r_bandedge_nonzero_cfg_sbw160_{n} (n=0..3)
0xD90C REG_AX_PWR_TSSI_TABLE1
  [8n-25:8n-32] r_bandedge_nonzero_cfg_sbw160_{n} (n=4..7)
0xD910 REG_AX_PWR_TSSI_TABLE2
  [31:24] r_bandedge_nonzero_cfg_sbw80_0, [23:16] r_bandedge_nonzero_cfg_sbw40_1, [15:8] r_bandedge_nonzero_cfg_sbw40_0, [7:0] r_bandedge_nonzero_cfg_sbw20
0xD914 REG_AX_PWR_TSSI_TABLE3
  [31:24] r_bandedge_zero_cfg_sbw160_0, [23:16] r_bandedge_nonzero_cfg_sbw80_3, [15:8] r_bandedge_nonzero_cfg_sbw80_2, [7:0] r_bandedge_nonzero_cfg_sbw80_1
0xD918 REG_AX_PWR_TSSI_TABLE4
  [8n-1:8n-8] r_bandedge_zero_cfg_sbw160_{n} (n=1..4)
0xD91C REG_AX_PWR_TSSI_TABLE5
  [31:24] r_bandedge_zero_cfg_sbw20, [23:16] r_bandedge_zero_cfg_sbw160_7, [15:8] r_bandedge_zero_cfg_sbw160_6, [7:0] r_bandedge_zero_cfg_sbw160_5
0xD920 REG_AX_PWR_TSSI_TABLE6
  [31:24] r_bandedge_zero_cfg_sbw80_1, [23:16] r_bandedge_zero_cfg_sbw80_0, [15:8] r_bandedge_zero_cfg_sbw40_1, [7:0] r_bandedge_zero_cfg_sbw40_0
0xD924 REG_AX_PWR_TSSI_TABLE7
  [31:24] r_bmode_init_ofst_seg0_db, [23:16] r_bmode_init_diff_seg0_db, [15:8] r_bandedge_zero_cfg_sbw80_3, [7:0] r_bandedge_zero_cfg_sbw80_2
0xD928 REG_AX_PWR_TSSI_TABLE8
  [8n+7:8n] r_cbw_sub20_{n} (n=0..3)
0xD92C REG_AX_PWR_TSSI_TABLE9
  [8n-25:8n-32] r_cbw_sub20_{n} (n=4..7)
0xD930 REG_AX_PWR_TSSI_TABLE10
  [31:24] r_ch_comb_ofst_bandedge_nonzero_bw40, [23:16] r_ch_comb_ofst_bandedge_nonzero_bw20, [15:8] r_ch_comb_ofst_bandedge_nonzero_bw160, [7:0] r_ch_comb_common_diff_db
0xD934 REG_AX_PWR_TSSI_TABLE11
  [31:24] r_ch_comb_ofst_bandedge_zero_bw40, [23:16] r_ch_comb_ofst_bandedge_zero_bw20, [15:8] r_ch_comb_ofst_bandedge_zero_bw160, [7:0] r_ch_comb_ofst_bandedge_nonzero_bw80
0xD938 REG_AX_PWR_TSSI_TABLE12
  [31:24] r_f_pwr_ofst_out_seg0_db, [23:16] r_f_ch20_with_data_nonlegacy_val, [15:8] r_f_ch20_with_data_legacy_val, [7:0] r_ch_comb_ofst_bandedge_zero_bw80
0xD93C REG_AX_PWR_TSSI_TABLE13
  [31:24] r_hemu_init_diff_seg0_db, [23:16] r_heer_init_ofst_seg0_db, [15:8] r_heer_init_diff_seg0_db, [7:0] r_f_tssi_diff_out_seg0_db
0xD940 REG_AX_PWR_TSSI_TABLE14
  [31:24] r_hetb_init_diff_athestf_seg0_db, [23:16] r_hesu_init_ofst_seg0_db, [15:8] r_hesu_init_diff_seg0_db, [7:0] r_hemu_init_ofst_seg0_db
0xD944 REG_AX_PWR_TSSI_TABLE15
  [31:24] r_ht_init_diff_seg0_db, [23:16] r_hetb_init_ofst_seg0_db, [15:8] r_hetb_init_ofst_athestf_seg0_db, [7:0] r_hetb_init_diff_seg0_db
0xD948 REG_AX_PWR_TSSI_TABLE16
  [31:24] r_vht_init_diff_seg0_db, [23:16] r_legacy_init_ofst_seg0_db, [15:8] r_legacy_init_diff_seg0_db, [7:0] r_ht_init_ofst_seg0_db
0xD94C REG_AX_PWR_TSSI_TABLE17
  [31:30] r_bandedge_cfg, [29:26] r_f_rate_idx, [25:22] r_f_format, [21:18] r_bandedge_nonlegacy_rateidx_th, [17:14] r_bandedge_legacy_rateidx_th, [13:8] r_tssi_ctrl_mac_dbg_sel, [7:0] r_vht_init_ofst_seg0_db
0xD950 REG_AX_PWR_TSSI_TABLE18
  [31] r_f_heer_bypass_cbw_fltr_en, [30] r_f_heer_bandedge_ind_val, [29] r_f_heer_bandedge_ind_en, [28] r_f_format_en, [27] r_f_fast_mode_comp_init_en, [26] r_f_dbw_en, [25] r_f_ch20_with_data_en, [24] r_f_cbw_en, [23] r_f_bmode_ofst_out_en, [22] r_f_bmode_diff_out_en, [21] r_f_bmode_bypass_dbw_fltr_en, [20] r_f_bmode_bypass_cbw_fltr_en, [19] r_f_bmode_bandedge_ind_val, [18] r_f_bmode_bandedge_ind_en, [17] r_f_bandedge_cfg_sustbc_en, [16] r_f_bandedge_cfg_sudcm_en, [15] r_f_bandedge_cfg_subf_en, [14] r_f_bandedge_cfg_ndp_en, [13] r_f_bandedge_cfg_mu_en, [12] r_f_bandedge_cfg_hetb_en, [11] r_ch20_with_data_nonlegacy_swap, [10] r_ch20_with_data_legacy_swap, [9:8] r_f_precoding_mode_idx, [7:6] r_f_dbw, [5:4] r_f_cbw, [3:0] r_f_txsc
0xD954 REG_AX_PWR_TSSI_TABLE19
  [31] r_f_is_su_stbc, [30] r_f_is_su_dcm_en, [29] r_f_is_su_dcm, [28] r_f_is_ndp_en, [27] r_f_is_ndp, [26] r_f_ht_ofst_out_en, [25] r_f_ht_diff_out_en, [24] r_f_ht_bypass_dbw_fltr_en, [23] r_f_ht_bypass_cbw_fltr_en, [22] r_f_ht_bandedge_ind_val, [21] r_f_ht_bandedge_ind_en, [20] r_f_hetb_ofst_out_en, [19] r_f_hetb_diff_out_en, [18] r_f_hetb_bypass_dbw_fltr_en, [17] r_f_hetb_bypass_cbw_fltr_en, [16] r_f_hetb_bandedge_ind_val, [15] r_f_hetb_bandedge_ind_en, [14] r_f_hesu_ofst_out_en, [13] r_f_hesu_diff_out_en, [12] r_f_hesu_bypass_dbw_fltr_en, [11] r_f_hesu_bypass_cbw_fltr_en, [10] r_f_hesu_bandedge_ind_val, [9] r_f_hesu_bandedge_ind_en, [8] r_f_hemu_ofst_out_en, [7] r_f_hemu_diff_out_en, [6] r_f_hemu_bypass_dbw_fltr_en, [5] r_f_hemu_bypass_cbw_fltr_en, [4] r_f_hemu_bandedge_ind_val, [3] r_f_hemu_bandedge_ind_en, [2] r_f_heer_ofst_out_en, [1] r_f_heer_diff_out_en, [0] r_f_heer_bypass_dbw_fltr_en
0xD958 REG_AX_PWR_TSSI_TABLE20
  [22] r_tssi_ctrl_mac_use_normal_rate_idx_only, [21] r_tssi_ctrl_mac_dbg_dis, [20] r_tssi_ctrl_mac_clr, [19] r_hetb_pwr_msr_mode, [18] r_f_vht_ofst_out_en, [17] r_f_vht_diff_out_en, [16] r_f_vht_bypass_dbw_fltr_en, [15] r_f_vht_bypass_cbw_fltr_en, [14] r_f_vht_bandedge_ind_val, [13] r_f_vht_bandedge_ind_en, [12] r_f_txsc_en, [11] r_f_tssi_ctrl_out_en, [10] r_f_tssi_ctrl_fast_mode_idx_en, [9] r_f_tssi_ctrl_fast_mode_idx, [8] r_f_rate_idx_en, [7] r_f_precoding_mode_idx_en, [6] r_f_legacy_ofst_out_en, [5] r_f_legacy_diff_out_en, [4] r_f_legacy_bypass_dbw_fltr_en, [3] r_f_legacy_bypass_cbw_fltr_en, [2] r_f_legacy_bandedge_ind_val, [1] r_f_legacy_bandedge_ind_en, [0] r_f_is_su_stbc_en
